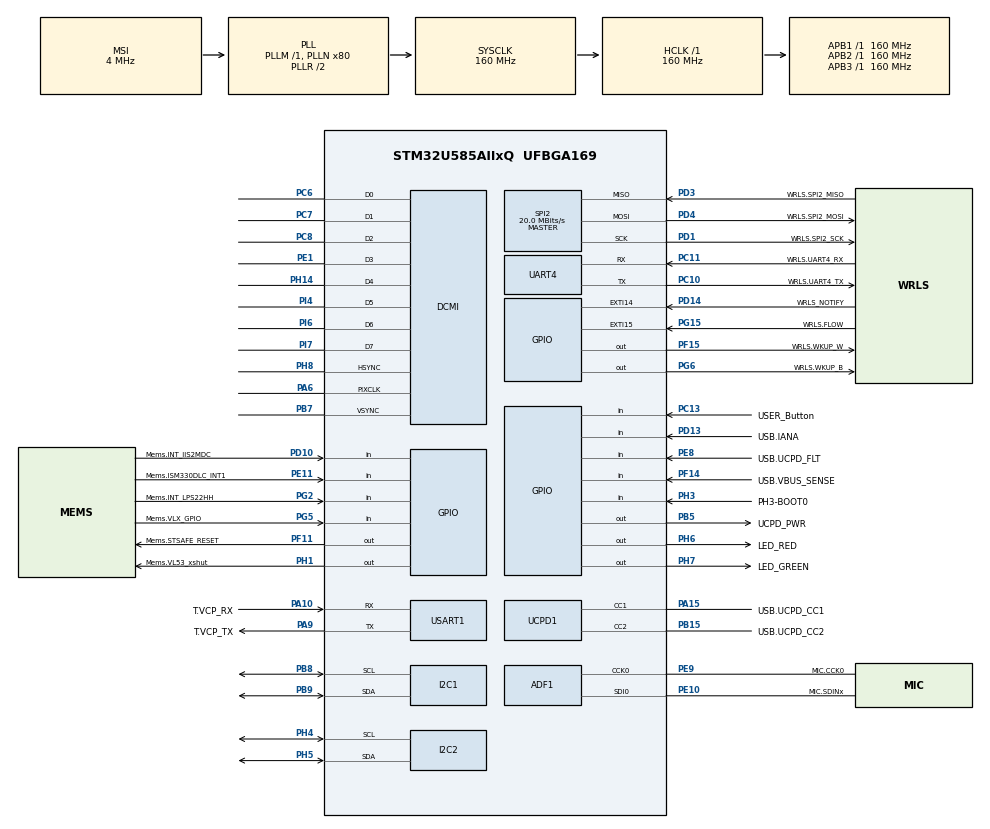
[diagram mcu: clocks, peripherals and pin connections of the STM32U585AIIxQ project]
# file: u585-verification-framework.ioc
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CORTEX_M33_NS.userName=CORTEX_M33
DCMI.HSPolarity=DCMI_HSPOLARITY_HIGH
DCMI.JPEGMode=DCMI_JPEG_ENABLE
DCMI.PCKPolarity=DCMI_PCKPOLARITY_RISING
DCMI.VSPolarity=DCMI_VSPOLARITY_HIGH
GPDMA1.DESTDATAWIDTH_GPDMACH0=DMA_DEST_DATAWIDTH_WORD
GPDMA1.DESTINC_GPDMACH0=DMA_DINC_INCREMENTED
GPDMA1.DESTINC_GPDMACH4=DMA_DINC_INCREMENTED
GPDMA1.IPHANDLE_GPDMACH0-SIMPLEREQUEST_GPDMACH0=__NULL
GPDMA1.IPHANDLE_GPDMACH4-SIMPLEREQUEST_GPDMACH4=__NULL
GPDMA1.IPHANDLE_GPDMACH5-SIMPLEREQUEST_GPDMACH5=__NULL
GPDMA1.PRIORITY_GPDMACH4=DMA_LOW_PRIORITY_HIGH_WEIGHT
GPDMA1.PRIORITY_GPDMACH5=DMA_LOW_PRIORITY_HIGH_WEIGHT
GPDMA1.RECAP_GPDMACH0=GPDMA1_REQUEST_DCMI
GPDMA1.REQUEST_GPDMACH0=GPDMA1_REQUEST_DCMI_PSSI
GPDMA1.REQUEST_GPDMACH4=GPDMA1_REQUEST_SPI2_RX
GPDMA1.REQUEST_GPDMACH5=GPDMA1_REQUEST_SPI2_TX
GPDMA1.SRCDATAWIDTH_GPDMACH0=DMA_SRC_DATAWIDTH_WORD
GPDMA1.SRCINC_GPDMACH5=DMA_SINC_INCREMENTED
GPDMA1.TRANSFERALLOCATEDPORTDEST_GPDMACH0=DMA_DEST_ALLOCATED_PORT1
GPDMA1.TRANSFERALLOCATEDPORTDEST_GPDMACH4=DMA_DEST_ALLOCATED_PORT1
GPDMA1.TRANSFERALLOCATEDPORTDEST_GPDMACH5=DMA_DEST_ALLOCATED_PORT1
I2C1.Timing=0x30909DEC
I2C2.Timing=0x30909DEC
Mcu.Family=STM32U5
Mcu.Name=STM32U585AIIxQ
Mcu.Package=UFBGA169
NETXDUO.NX_APP_MEM_POOL_SIZE=200*1024
NETXDUO.NX_DRIVER_DEFERRED_PROCESSING=true
NETXDUO.NX_ENABLE_EXTENDED_NOTIFY_SUPPORT=true
NETXDUO.NX_ENABLE_IP_PACKET_FILTER=true
NETXDUO.NX_PHYSICAL_HEADER=44
NVIC.DCMI_PSSI_IRQn=true\:0\:0\:false\:false\:true\:false\:true\:true\:true
NVIC.EXTI14_IRQn=true\:0\:0\:false\:false\:true\:false\:true\:true\:true
NVIC.EXTI15_IRQn=true\:0\:0\:false\:false\:true\:false\:true\:true\:true
NVIC.GPDMA1_Channel0_IRQn=true\:0\:0\:false\:false\:true\:true\:false\:true\:true
NVIC.GPDMA1_Channel4_IRQn=true\:0\:0\:false\:false\:true\:true\:false\:true\:true
NVIC.GPDMA1_Channel5_IRQn=true\:0\:0\:false\:false\:true\:true\:false\:true\:true
NVIC.PriorityGroup=NVIC_PRIORITYGROUP_4
NVIC.SPI2_IRQn=true\:0\:0\:false\:false\:true\:false\:false\:true\:true
NVIC.TIM6_IRQn=true\:15\:0\:false\:false\:true\:false\:false\:true\:true
NVIC.TimeBase=TIM6_IRQn
NVIC.TimeBaseIP=TIM6
PA10.GPIO_Label=T.VCP_RX
PA10.Mode=Asynchronous
PA10.Signal=USART1_RX
PA11.GPIO_Label=USB.C_P
PA11.Signal=USB_OTG_FS_DM
PA12.GPIO_Label=USB.C_P
PA12.Signal=USB_OTG_FS_DP
PA13\ (JTMS/SWDIO).GPIO_Label=T.SWDIO
PA13\ (JTMS/SWDIO).Mode=Trace_Asynchronous_SW
PA13\ (JTMS/SWDIO).Signal=DEBUG_JTMS-SWDIO
PA14\ (JTCK/SWCLK).GPIO_Label=T.SWCLK
PA14\ (JTCK/SWCLK).Mode=Trace_Asynchronous_SW
PA14\ (JTCK/SWCLK).Signal=DEBUG_JTCK-SWCLK
PA15\ (JTDI).GPIO_Label=USB.UCPD_CC1
PA15\ (JTDI).Mode=Dual_Role_AllSignals
PA15\ (JTDI).Signal=UCPD1_CC1
PA6.Mode=Slave_8_bits_External_Synchro
PA6.Signal=DCMI_PIXCLK
PA9.GPIO_Label=T.VCP_TX
PA9.Mode=Asynchronous
PA9.Signal=USART1_TX
PB1.GPIO_Label=MIC.SDIN0
PB1.Signal=MDF1_SDI0
PB10.GPIO_Label=OCTOSPI.R_CLK_P
PB10.Signal=OCTOSPIM_P1_CLK
PB11.GPIO_Label=OCTOSPI.R_NCS
PB11.Signal=OCTOSPIM_P1_NCS
PB12.GPIO_Label=WRLS.SPI2_NSS
PB12.Signal=SPI2_NSS
PB15.GPIO_Label=USB.UCPD_CC2
PB15.Mode=Dual_Role_AllSignals
PB15.Signal=UCPD1_CC2
PB3\ (JTDO/TRACESWO).GPIO_Label=T.SWO
PB3\ (JTDO/TRACESWO).Mode=Trace_Asynchronous_SW
PB3\ (JTDO/TRACESWO).Signal=DEBUG_JTDO-SWO
PB5.GPIO_Label=UCPD_PWR
PB5.Signal=GPIO_Output
PB7.Mode=Slave_8_bits_External_Synchro
PB7.Signal=DCMI_VSYNC
PB8.Mode=I2C
PB8.Signal=I2C1_SCL
PB9.Mode=I2C
PB9.Signal=I2C1_SDA
PC10.GPIO_Label=WRLS.UART4_TX
PC10.Mode=Asynchronous
PC10.Signal=UART4_TX
PC11.GPIO_Label=WRLS.UART4_RX
PC11.Mode=Asynchronous
PC11.Signal=UART4_RX
PC13.GPIO_Label=USER_Button
PC13.Signal=GPIO_Input
PC14-OSC32_IN\ (PC14).GPIO_Label=PC14-OSC32_IN
PC14-OSC32_IN\ (PC14).Mode=LSE-External-Oscillator
PC14-OSC32_IN\ (PC14).Signal=RCC_OSC32_IN
PC15-OSC32_OUT\ (PC15).GPIO_Label=PC15-OSC32_OUT
PC15-OSC32_OUT\ (PC15).Mode=LSE-External-Oscillator
PC15-OSC32_OUT\ (PC15).Signal=RCC_OSC32_OUT
PC3.GPIO_Label=OCTOSPI.R_IO6
PC3.Signal=OCTOSPIM_P1_IO6
PC6.Mode=Slave_8_bits_External_Synchro
PC6.Signal=DCMI_D0
PC7.Mode=Slave_8_bits_External_Synchro
PC7.Signal=DCMI_D1
PC8.Mode=Slave_8_bits_External_Synchro
PC8.Signal=DCMI_D2
PD1.GPIO_Label=WRLS.SPI2_SCK
PD1.Mode=Full_Duplex_Master
PD1.Signal=SPI2_SCK
PD10.GPIO_Label=Mems.INT_IIS2MDC
PD10.Signal=GPIO_Input
PD13.GPIO_Label=USB.IANA
PD13.Signal=GPIO_Input
PD14.GPIO_Label=WRLS_NOTIFY 
PD14.Signal=GPXTI14
PD3.GPIO_Label=WRLS.SPI2_MISO
PD3.Mode=Full_Duplex_Master
PD3.Signal=SPI2_MISO
PD4.GPIO_Label=WRLS.SPI2_MOSI
PD4.Mode=Full_Duplex_Master
PD4.Signal=SPI2_MOSI
PD7.GPIO_Label=OCTOSPI.R_IO7
PD7.Signal=OCTOSPIM_P1_IO7
PE1.Mode=Slave_8_bits_External_Synchro
PE1.Signal=DCMI_D3
PE10.GPIO_Label=MIC.SDINx
PE10.Mode=MOD_ADF_CCK
PE10.Signal=ADF1_SDI0
PE11.GPIO_Label=Mems.ISM330DLC_INT1
PE11.Signal=GPIO_Input
PE3.GPIO_Label=OCTOSPI.R_DQS
PE3.Signal=OCTOSPIM_P1_DQS
PE8.GPIO_Label=USB.UCPD_FLT
PE8.Signal=GPIO_Input
PE9.GPIO_Label=MIC.CCK0
PE9.Mode=MOD_MDF_CCK0
PE9.Signal=ADF1_CCK0
PF0.GPIO_Label=OCTOSPI.F_IO0
PF0.Signal=OCTOSPIM_P2_IO0
PF1.GPIO_Label=OCTOSPI.F_IO1
PF1.Signal=OCTOSPIM_P2_IO1
PF10.GPIO_Label=MIC.CCK1
PF10.Signal=MDF1_CCK1
PF11.GPIO_Label=Mems.STSAFE_RESET
PF11.Signal=GPIO_Output
PF12.GPIO_Label=OCTOSPI.F_DQS
PF12.Signal=OCTOSPIM_P2_DQS
PF14.GPIO_Label=USB.VBUS_SENSE
PF14.Signal=GPIO_Input
PF15.GPIO_Label=WRLS.WKUP_W
PF15.Signal=GPIO_Output
PF2.GPIO_Label=OCTOSPI.F_IO2
PF2.Signal=OCTOSPIM_P2_IO2
PF3.GPIO_Label=OCTOSPI.F_IO3
PF3.Signal=OCTOSPIM_P2_IO3
PF4.GPIO_Label=OCTOSPI.F_CLK_P
PF4.Signal=OCTOSPIM_P2_CLK
PF6.GPIO_Label=OCTOSPI.R_IO3
PF6.Signal=OCTOSPIM_P1_IO3
PF7.GPIO_Label=OCTOSPI.R_IO2
PF7.Signal=OCTOSPIM_P1_IO2
PF8.GPIO_Label=OCTOSPI.R_IO0
PF8.Signal=OCTOSPIM_P1_IO0
PF9.GPIO_Label=OCTOSPI.R_IO1
PF9.Signal=OCTOSPIM_P1_IO1
PG15.GPIO_Label=WRLS.FLOW
PG15.Signal=GPXTI15
PG2.GPIO_Label=Mems.INT_LPS22HH
PG2.Signal=GPIO_Input
PG5.GPIO_Label=Mems.VLX_GPIO
PG5.Signal=GPIO_Input
PG6.GPIO_Label=WRLS.WKUP_B
PG6.Signal=GPIO_Output
PH1-OSC_OUT\ (PH1).GPIO_Label=Mems.VL53_xshut
PH1-OSC_OUT\ (PH1).Signal=GPIO_Output
PH10.GPIO_Label=OCTOSPI.F_IO5
PH10.Signal=OCTOSPIM_P2_IO5
PH11.GPIO_Label=OCTOSPI.F_IO6
PH11.Signal=OCTOSPIM_P2_IO6
PH12.GPIO_Label=OCTOSPI.F_IO7
PH12.Signal=OCTOSPIM_P2_IO7
PH14.Mode=Slave_8_bits_External_Synchro
PH14.Signal=DCMI_D4
PH2.GPIO_Label=OCTOSPI.R_IO4
PH2.Signal=OCTOSPIM_P1_IO4
PH3-BOOT0.GPIO_Label=PH3-BOOT0
PH3-BOOT0.Signal=GPIO_Input
PH4.Mode=I2C
PH4.Signal=I2C2_SCL
PH5.Mode=I2C
PH5.Signal=I2C2_SDA
PH6.GPIO_Label=LED_RED
PH6.Signal=GPIO_Output
PH7.GPIO_Label=LED_GREEN
PH7.Signal=GPIO_Output
PH8.Mode=Slave_8_bits_External_Synchro
PH8.Signal=DCMI_HSYNC
PH9.GPIO_Label=OCTOSPI.F_IO4
PH9.Signal=OCTOSPIM_P2_IO4
PI0.GPIO_Label=OCTOSPI.R_IO5
PI0.Signal=OCTOSPIM_P1_IO5
PI4.Mode=Slave_8_bits_External_Synchro
PI4.Signal=DCMI_D5
PI5.GPIO_Label=OCTOSPI.F_NCS
PI5.Signal=OCTOSPIM_P2_NCS
PI6.Mode=Slave_8_bits_External_Synchro
PI6.Signal=DCMI_D6
PI7.Mode=Slave_8_bits_External_Synchro
PI7.Signal=DCMI_D7
PWR.PowerMode=PWR_SMPS_SUPPLY
ProjectManager.HeapSize=0x200
ProjectManager.StackSize=0x400
ProjectManager.TargetToolchain=CMake
RCC.ADCFreq_Value=16000000
RCC.AHBFreq_Value=160000000
RCC.APB1Freq_Value=160000000
RCC.APB1TimFreq_Value=160000000
RCC.APB2Freq_Value=160000000
RCC.APB2TimFreq_Value=160000000
RCC.APB3Freq_Value=160000000
RCC.CortexFreq_Value=160000000
RCC.DACCLockSelectionVirtual=RCC_DAC1CLKSOURCE_LSI
RCC.EPOD_VALUE=4000000
RCC.HCLKFreq_Value=160000000
RCC.HSE_VALUE=16000000
RCC.HSI48_VALUE=48000000
RCC.HSI_VALUE=16000000
RCC.LSIDIV_VALUE=32000
RCC.MSI_VALUE=4000000
RCC.PLLN=80
RCC.SYSCLKFreq_VALUE=160000000
RCC.SYSCLKSource=RCC_SYSCLKSOURCE_PLLCLK
RCC.USBFreq_Value=48000000
RCC.VCOOutputFreq_Value=320000000
SPI2.BaudRatePrescaler=SPI_BAUDRATEPRESCALER_8
SPI2.CalculateBaudRate=20.0 MBits/s
SPI2.DataSize=SPI_DATASIZE_8BIT
SPI2.Direction=SPI_DIRECTION_2LINES
SPI2.Mode=SPI_MODE_MASTER
SPI2.NSSPMode=SPI_NSS_PULSE_DISABLE
SPI2.VirtualType=VM_MASTER
THREADX.TX_APP_MEM_POOL_SIZE=4096
USART1.VirtualMode-Asynchronous=VM_ASYNC
VP_GPDMA1_VS_GPDMACH0.Mode=SIMPLEREQUEST_GPDMACH0
VP_GPDMA1_VS_GPDMACH4.Mode=SIMPLEREQUEST_GPDMACH4
VP_GPDMA1_VS_GPDMACH5.Mode=SIMPLEREQUEST_GPDMACH5
VP_ICACHE_VS_ICACHE.Mode=DirectMappedCache
VP_LPBAMQUEUE_VS_QUEUE.Mode=QUEUEMODE
VP_LPBAM_VS_SIG1.Mode=SmartRun
VP_LPBAM_VS_SIG4.Mode=LPDMA1
VP_MEMORYMAP_VS_MEMORYMAP.Mode=CurAppReg
VP_NETXDUO_VS_AddonsOoDHCP.Mode=Addons_DHCP_Client
VP_NETXDUO_VS_AddonsOoWebOoServer.Mode=Addons_Web_Server
VP_NETXDUO_VS_NXOoCore.Mode=NX_Core
VP_PWR_VS_DBSignals.Mode=DisableDeadBatterySignals
VP_PWR_VS_LPOM.Mode=PowerOptimisation
VP_PWR_VS_SECSignals.Mode=Security/Privilege
VP_SYS_VS_tim6.Mode=TIM6
VP_THREADX_VS_RTOSJjThreadXJjCoreJjDefault.Mode=Core_Default
VP_THREADX_VS_RTOSJjThreadXJjPerformance_InfoJjDefault.Mode=Performance_Default
board=B-U585I-IOT02A

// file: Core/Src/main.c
/* USER CODE BEGIN Header */
/**
  ******************************************************************************
  * @file           : main.c
  * @brief          : Main program body
  ******************************************************************************
  * @attention
  *
  * Copyright (c) 2026 STMicroelectronics.
  * All rights reserved.
  *
  * This software is licensed under terms that can be found in the LICENSE file
  * in the root directory of this software component.
  * If no LICENSE file comes with this software, it is provided AS-IS.
  *
  ******************************************************************************
  */
/* USER CODE END Header */
#include "app_threadx.h"
#include "main.h"

/* USER CODE BEGIN Includes */

#include "system.h"

/* USER CODE END Includes */

MDF_HandleTypeDef AdfHandle0;
MDF_FilterConfigTypeDef AdfFilterConfig0;

DCMI_HandleTypeDef hdcmi;
DMA_HandleTypeDef handle_GPDMA1_Channel0;

I2C_HandleTypeDef hi2c1;
I2C_HandleTypeDef hi2c2;

SPI_HandleTypeDef hspi2;
DMA_HandleTypeDef handle_GPDMA1_Channel5;
DMA_HandleTypeDef handle_GPDMA1_Channel4;

UART_HandleTypeDef huart4;
UART_HandleTypeDef huart1;

void SystemClock_Config(void);
static void SystemPower_Config(void);
static void MX_GPIO_Init(void);
static void MX_GPDMA1_Init(void);
static void MX_ADF1_Init(void);
static void MX_I2C1_Init(void);
static void MX_I2C2_Init(void);
static void MX_ICACHE_Init(void);
static void MX_SPI2_Init(void);
static void MX_UART4_Init(void);
static void MX_USART1_UART_Init(void);
static void MX_DCMI_Init(void);
static void MX_UCPD1_Init(void);

int main(void)
{

  /* MCU Configuration--------------------------------------------------------*/

  /* Reset of all peripherals, Initializes the Flash interface and the Systick. */
  HAL_Init();

  /* Configure the System Power */
  SystemPower_Config();

  /* Configure the system clock */
  SystemClock_Config();

  /* Initialize all configured peripherals */
  MX_GPIO_Init();
  MX_GPDMA1_Init();
  MX_ADF1_Init();
  MX_I2C1_Init();
  MX_I2C2_Init();
  MX_ICACHE_Init();
  MX_SPI2_Init();
  MX_UART4_Init();
  MX_USART1_UART_Init();
  MX_DCMI_Init();
  MX_UCPD1_Init();
  /* USER CODE BEGIN 2 */

  System_Init();

  /* USER CODE END 2 */

  MX_ThreadX_Init();

  /* We should never get here as control is now taken by the scheduler */

  /* Infinite loop */
  while (1)
  {

    /* USER CODE BEGIN 3 */

    /* Unreachable: tx_kernel_enter() inside MX_ThreadX_Init() above never
     * returns. Sensor polling now runs in the "System Thread" started by
     * App_ThreadX_Init() (Core/Src/app_threadx.c). */

  }
  /* USER CODE END 3 */
}

void SystemClock_Config(void)
{
  RCC_OscInitTypeDef RCC_OscInitStruct = {0};
  RCC_ClkInitTypeDef RCC_ClkInitStruct = {0};

  /** Configure the main internal regulator output voltage
  */
  if (HAL_PWREx_ControlVoltageScaling(PWR_REGULATOR_VOLTAGE_SCALE1) != HAL_OK)
  {
    Error_Handler();
  }

  /** Initializes the CPU, AHB and APB buses clocks
  */
  RCC_OscInitStruct.OscillatorType = RCC_OSCILLATORTYPE_HSI|RCC_OSCILLATORTYPE_MSI;
  RCC_OscInitStruct.HSIState = RCC_HSI_ON;
  RCC_OscInitStruct.HSICalibrationValue = RCC_HSICALIBRATION_DEFAULT;
  RCC_OscInitStruct.MSIState = RCC_MSI_ON;
  RCC_OscInitStruct.MSICalibrationValue = RCC_MSICALIBRATION_DEFAULT;
  RCC_OscInitStruct.MSIClockRange = RCC_MSIRANGE_4;
  RCC_OscInitStruct.PLL.PLLState = RCC_PLL_ON;
  RCC_OscInitStruct.PLL.PLLSource = RCC_PLLSOURCE_MSI;
  RCC_OscInitStruct.PLL.PLLMBOOST = RCC_PLLMBOOST_DIV1;
  RCC_OscInitStruct.PLL.PLLM = 1;
  RCC_OscInitStruct.PLL.PLLN = 80;
  RCC_OscInitStruct.PLL.PLLP = 2;
  RCC_OscInitStruct.PLL.PLLQ = 2;
  RCC_OscInitStruct.PLL.PLLR = 2;
  RCC_OscInitStruct.PLL.PLLRGE = RCC_PLLVCIRANGE_0;
  RCC_OscInitStruct.PLL.PLLFRACN = 0;
  if (HAL_RCC_OscConfig(&RCC_OscInitStruct) != HAL_OK)
  {
    Error_Handler();
  }

  /** Initializes the CPU, AHB and APB buses clocks
  */
  RCC_ClkInitStruct.ClockType = RCC_CLOCKTYPE_HCLK|RCC_CLOCKTYPE_SYSCLK
                              |RCC_CLOCKTYPE_PCLK1|RCC_CLOCKTYPE_PCLK2
                              |RCC_CLOCKTYPE_PCLK3;
  RCC_ClkInitStruct.SYSCLKSource = RCC_SYSCLKSOURCE_PLLCLK;
  RCC_ClkInitStruct.AHBCLKDivider = RCC_SYSCLK_DIV1;
  RCC_ClkInitStruct.APB1CLKDivider = RCC_HCLK_DIV1;
  RCC_ClkInitStruct.APB2CLKDivider = RCC_HCLK_DIV1;
  RCC_ClkInitStruct.APB3CLKDivider = RCC_HCLK_DIV1;

  if (HAL_RCC_ClockConfig(&RCC_ClkInitStruct, FLASH_LATENCY_4) != HAL_OK)
  {
    Error_Handler();
  }
}

/**
  * @brief Power Configuration
  * @retval None
  */
static void SystemPower_Config(void)
{
  HAL_PWREx_EnableVddIO2();

  /*
   * Switch to SMPS regulator instead of LDO
   */
  if (HAL_PWREx_ConfigSupply(PWR_SMPS_SUPPLY) != HAL_OK)
  {
    Error_Handler();
  }
}

static void MX_ADF1_Init(void)
{

  /**
    AdfHandle0 structure initialization and HAL_MDF_Init function call
  */
  AdfHandle0.Instance = ADF1_Filter0;
  AdfHandle0.Init.CommonParam.ProcClockDivider = 1;
  AdfHandle0.Init.CommonParam.OutputClock.Activation = DISABLE;
  AdfHandle0.Init.SerialInterface.Activation = ENABLE;
  AdfHandle0.Init.SerialInterface.Mode = MDF_SITF_LF_MASTER_SPI_MODE;
  AdfHandle0.Init.SerialInterface.ClockSource = MDF_SITF_CCK0_SOURCE;
  AdfHandle0.Init.SerialInterface.Threshold = 4;
  AdfHandle0.Init.FilterBistream = MDF_BITSTREAM0_FALLING;
  if (HAL_MDF_Init(&AdfHandle0) != HAL_OK)
  {
    Error_Handler();
  }

  /**
    AdfFilterConfig0 structure initialization

    WARNING : only structure is filled, no specific init function call for filter
  */
  AdfFilterConfig0.DataSource = MDF_DATA_SOURCE_BSMX;
  AdfFilterConfig0.Delay = 0;
  AdfFilterConfig0.CicMode = MDF_ONE_FILTER_SINC4;
  AdfFilterConfig0.DecimationRatio = 2;
  AdfFilterConfig0.Gain = 0;
  AdfFilterConfig0.ReshapeFilter.Activation = DISABLE;
  AdfFilterConfig0.HighPassFilter.Activation = DISABLE;
  AdfFilterConfig0.SoundActivity.Activation = DISABLE;
  AdfFilterConfig0.AcquisitionMode = MDF_MODE_ASYNC_CONT;
  AdfFilterConfig0.FifoThreshold = MDF_FIFO_THRESHOLD_NOT_EMPTY;
  AdfFilterConfig0.DiscardSamples = 0;

}

static void MX_DCMI_Init(void)
{

  hdcmi.Instance = DCMI;
  hdcmi.Init.SynchroMode = DCMI_SYNCHRO_HARDWARE;
  hdcmi.Init.PCKPolarity = DCMI_PCKPOLARITY_RISING;
  hdcmi.Init.VSPolarity = DCMI_VSPOLARITY_HIGH;
  hdcmi.Init.HSPolarity = DCMI_HSPOLARITY_HIGH;
  hdcmi.Init.CaptureRate = DCMI_CR_ALL_FRAME;
  hdcmi.Init.ExtendedDataMode = DCMI_EXTEND_DATA_8B;
  hdcmi.Init.JPEGMode = DCMI_JPEG_ENABLE;
  hdcmi.Init.ByteSelectMode = DCMI_BSM_ALL;
  hdcmi.Init.ByteSelectStart = DCMI_OEBS_ODD;
  hdcmi.Init.LineSelectMode = DCMI_LSM_ALL;
  hdcmi.Init.LineSelectStart = DCMI_OELS_ODD;
  if (HAL_DCMI_Init(&hdcmi) != HAL_OK)
  {
    Error_Handler();
  }

}

static void MX_GPDMA1_Init(void)
{

  /* Peripheral clock enable */
  __HAL_RCC_GPDMA1_CLK_ENABLE();

  /* GPDMA1 interrupt Init */
    HAL_NVIC_SetPriority(GPDMA1_Channel0_IRQn, 0, 0);
    HAL_NVIC_EnableIRQ(GPDMA1_Channel0_IRQn);
    HAL_NVIC_SetPriority(GPDMA1_Channel4_IRQn, 0, 0);
    HAL_NVIC_EnableIRQ(GPDMA1_Channel4_IRQn);
    HAL_NVIC_SetPriority(GPDMA1_Channel5_IRQn, 0, 0);
    HAL_NVIC_EnableIRQ(GPDMA1_Channel5_IRQn);

}

static void MX_I2C1_Init(void)
{

  hi2c1.Instance = I2C1;
  hi2c1.Init.Timing = 0x30909DEC;
  hi2c1.Init.OwnAddress1 = 0;
  hi2c1.Init.AddressingMode = I2C_ADDRESSINGMODE_7BIT;
  hi2c1.Init.DualAddressMode = I2C_DUALADDRESS_DISABLE;
  hi2c1.Init.OwnAddress2 = 0;
  hi2c1.Init.OwnAddress2Masks = I2C_OA2_NOMASK;
  hi2c1.Init.GeneralCallMode = I2C_GENERALCALL_DISABLE;
  hi2c1.Init.NoStretchMode = I2C_NOSTRETCH_DISABLE;
  if (HAL_I2C_Init(&hi2c1) != HAL_OK)
  {
    Error_Handler();
  }

  /** Configure Analogue filter
  */
  if (HAL_I2CEx_ConfigAnalogFilter(&hi2c1, I2C_ANALOGFILTER_ENABLE) != HAL_OK)
  {
    Error_Handler();
  }

  /** Configure Digital filter
  */
  if (HAL_I2CEx_ConfigDigitalFilter(&hi2c1, 0) != HAL_OK)
  {
    Error_Handler();
  }

}

static void MX_I2C2_Init(void)
{

  hi2c2.Instance = I2C2;
  hi2c2.Init.Timing = 0x30909DEC;
  hi2c2.Init.OwnAddress1 = 0;
  hi2c2.Init.AddressingMode = I2C_ADDRESSINGMODE_7BIT;
  hi2c2.Init.DualAddressMode = I2C_DUALADDRESS_DISABLE;
  hi2c2.Init.OwnAddress2 = 0;
  hi2c2.Init.OwnAddress2Masks = I2C_OA2_NOMASK;
  hi2c2.Init.GeneralCallMode = I2C_GENERALCALL_DISABLE;
  hi2c2.Init.NoStretchMode = I2C_NOSTRETCH_DISABLE;
  if (HAL_I2C_Init(&hi2c2) != HAL_OK)
  {
    Error_Handler();
  }

  /** Configure Analogue filter
  */
  if (HAL_I2CEx_ConfigAnalogFilter(&hi2c2, I2C_ANALOGFILTER_ENABLE) != HAL_OK)
  {
    Error_Handler();
  }

  /** Configure Digital filter
  */
  if (HAL_I2CEx_ConfigDigitalFilter(&hi2c2, 0) != HAL_OK)
  {
    Error_Handler();
  }

}

static void MX_ICACHE_Init(void)
{

  /** Enable instruction cache in 1-way (direct mapped cache)
  */
  if (HAL_ICACHE_ConfigAssociativityMode(ICACHE_1WAY) != HAL_OK)
  {
    Error_Handler();
  }
  if (HAL_ICACHE_Enable() != HAL_OK)
  {
    Error_Handler();
  }

}

static void MX_SPI2_Init(void)
{

  SPI_AutonomousModeConfTypeDef HAL_SPI_AutonomousMode_Cfg_Struct = {0};

  /* SPI2 parameter configuration*/
  hspi2.Instance = SPI2;
  hspi2.Init.Mode = SPI_MODE_MASTER;
  hspi2.Init.Direction = SPI_DIRECTION_2LINES;
  hspi2.Init.DataSize = SPI_DATASIZE_8BIT;
  hspi2.Init.CLKPolarity = SPI_POLARITY_LOW;
  hspi2.Init.CLKPhase = SPI_PHASE_1EDGE;
  hspi2.Init.NSS = SPI_NSS_SOFT;
  hspi2.Init.BaudRatePrescaler = SPI_BAUDRATEPRESCALER_8;
  hspi2.Init.FirstBit = SPI_FIRSTBIT_MSB;
  hspi2.Init.TIMode = SPI_TIMODE_DISABLE;
  hspi2.Init.CRCCalculation = SPI_CRCCALCULATION_DISABLE;
  hspi2.Init.CRCPolynomial = 0x7;
  hspi2.Init.NSSPMode = SPI_NSS_PULSE_DISABLE;
  hspi2.Init.NSSPolarity = SPI_NSS_POLARITY_LOW;
  hspi2.Init.FifoThreshold = SPI_FIFO_THRESHOLD_01DATA;
  hspi2.Init.MasterSSIdleness = SPI_MASTER_SS_IDLENESS_00CYCLE;
  hspi2.Init.MasterInterDataIdleness = SPI_MASTER_INTERDATA_IDLENESS_00CYCLE;
  hspi2.Init.MasterReceiverAutoSusp = SPI_MASTER_RX_AUTOSUSP_DISABLE;
  hspi2.Init.MasterKeepIOState = SPI_MASTER_KEEP_IO_STATE_DISABLE;
  hspi2.Init.IOSwap = SPI_IO_SWAP_DISABLE;
  hspi2.Init.ReadyMasterManagement = SPI_RDY_MASTER_MANAGEMENT_INTERNALLY;
  hspi2.Init.ReadyPolarity = SPI_RDY_POLARITY_HIGH;
  if (HAL_SPI_Init(&hspi2) != HAL_OK)
  {
    Error_Handler();
  }
  HAL_SPI_AutonomousMode_Cfg_Struct.TriggerState = SPI_AUTO_MODE_DISABLE;
  HAL_SPI_AutonomousMode_Cfg_Struct.TriggerSelection = SPI_GRP1_GPDMA_CH0_TCF_TRG;
  HAL_SPI_AutonomousMode_Cfg_Struct.TriggerPolarity = SPI_TRIG_POLARITY_RISING;
  if (HAL_SPIEx_SetConfigAutonomousMode(&hspi2, &HAL_SPI_AutonomousMode_Cfg_Struct) != HAL_OK)
  {
    Error_Handler();
  }

}

static void MX_UART4_Init(void)
{

  huart4.Instance = UART4;
  huart4.Init.BaudRate = 115200;
  huart4.Init.WordLength = UART_WORDLENGTH_8B;
  huart4.Init.StopBits = UART_STOPBITS_1;
  huart4.Init.Parity = UART_PARITY_NONE;
  huart4.Init.Mode = UART_MODE_TX_RX;
  huart4.Init.HwFlowCtl = UART_HWCONTROL_NONE;
  huart4.Init.OverSampling = UART_OVERSAMPLING_16;
  huart4.Init.OneBitSampling = UART_ONE_BIT_SAMPLE_DISABLE;
  huart4.Init.ClockPrescaler = UART_PRESCALER_DIV1;
  huart4.AdvancedInit.AdvFeatureInit = UART_ADVFEATURE_NO_INIT;
  if (HAL_UART_Init(&huart4) != HAL_OK)
  {
    Error_Handler();
  }
  if (HAL_UARTEx_SetTxFifoThreshold(&huart4, UART_TXFIFO_THRESHOLD_1_8) != HAL_OK)
  {
    Error_Handler();
  }
  if (HAL_UARTEx_SetRxFifoThreshold(&huart4, UART_RXFIFO_THRESHOLD_1_8) != HAL_OK)
  {
    Error_Handler();
  }
  if (HAL_UARTEx_DisableFifoMode(&huart4) != HAL_OK)
  {
    Error_Handler();
  }

}

static void MX_USART1_UART_Init(void)
{

  huart1.Instance = USART1;
  huart1.Init.BaudRate = 115200;
  huart1.Init.WordLength = UART_WORDLENGTH_8B;
  huart1.Init.StopBits = UART_STOPBITS_1;
  huart1.Init.Parity = UART_PARITY_NONE;
  huart1.Init.Mode = UART_MODE_TX_RX;
  huart1.Init.HwFlowCtl = UART_HWCONTROL_NONE;
  huart1.Init.OverSampling = UART_OVERSAMPLING_16;
  huart1.Init.OneBitSampling = UART_ONE_BIT_SAMPLE_DISABLE;
  huart1.Init.ClockPrescaler = UART_PRESCALER_DIV1;
  huart1.AdvancedInit.AdvFeatureInit = UART_ADVFEATURE_NO_INIT;
  if (HAL_UART_Init(&huart1) != HAL_OK)
  {
    Error_Handler();
  }
  if (HAL_UARTEx_SetTxFifoThreshold(&huart1, UART_TXFIFO_THRESHOLD_1_8) != HAL_OK)
  {
    Error_Handler();
  }
  if (HAL_UARTEx_SetRxFifoThreshold(&huart1, UART_RXFIFO_THRESHOLD_1_8) != HAL_OK)
  {
    Error_Handler();
  }
  if (HAL_UARTEx_DisableFifoMode(&huart1) != HAL_OK)
  {
    Error_Handler();
  }

}

static void MX_UCPD1_Init(void)
{

  LL_GPIO_InitTypeDef GPIO_InitStruct = {0};

  /* Peripheral clock enable */
  LL_APB1_GRP2_EnableClock(LL_APB1_GRP2_PERIPH_UCPD1);

  LL_AHB2_GRP1_EnableClock(LL_AHB2_GRP1_PERIPH_GPIOA);
  LL_AHB2_GRP1_EnableClock(LL_AHB2_GRP1_PERIPH_GPIOB);
  /**UCPD1 GPIO Configuration
  PA15 (JTDI)   ------> UCPD1_CC1
  PB15   ------> UCPD1_CC2
  */
  GPIO_InitStruct.Pin = LL_GPIO_PIN_15;
  GPIO_InitStruct.Mode = LL_GPIO_MODE_ANALOG;
  GPIO_InitStruct.Pull = LL_GPIO_PULL_NO;
  LL_GPIO_Init(GPIOA, &GPIO_InitStruct);

  GPIO_InitStruct.Pin = LL_GPIO_PIN_15;
  GPIO_InitStruct.Mode = LL_GPIO_MODE_ANALOG;
  GPIO_InitStruct.Pull = LL_GPIO_PULL_NO;
  LL_GPIO_Init(GPIOB, &GPIO_InitStruct);

}

static void MX_GPIO_Init(void)
{
  GPIO_InitTypeDef GPIO_InitStruct = {0};

  /* GPIO Ports Clock Enable */
  __HAL_RCC_GPIOI_CLK_ENABLE();
  __HAL_RCC_GPIOG_CLK_ENABLE();
  __HAL_RCC_GPIOC_CLK_ENABLE();
  __HAL_RCC_GPIOA_CLK_ENABLE();
  __HAL_RCC_GPIOH_CLK_ENABLE();
  __HAL_RCC_GPIOE_CLK_ENABLE();
  __HAL_RCC_GPIOB_CLK_ENABLE();
  __HAL_RCC_GPIOD_CLK_ENABLE();
  __HAL_RCC_GPIOF_CLK_ENABLE();

  /*Configure GPIO pin Output Level */
  HAL_GPIO_WritePin(UCPD_PWR_GPIO_Port, UCPD_PWR_Pin, GPIO_PIN_RESET);

  /*Configure GPIO pin Output Level */
  HAL_GPIO_WritePin(GPIOH, LED_RED_Pin|LED_GREEN_Pin|Mems_VL53_xshut_Pin, GPIO_PIN_RESET);

  /*Configure GPIO pin Output Level */
  HAL_GPIO_WritePin(WRLS_WKUP_B_GPIO_Port, WRLS_WKUP_B_Pin, GPIO_PIN_RESET);

  /*Configure GPIO pin Output Level */
  HAL_GPIO_WritePin(GPIOF, Mems_STSAFE_RESET_Pin|WRLS_WKUP_W_Pin, GPIO_PIN_RESET);

  /*Configure GPIO pin : WRLS_FLOW_Pin */
  GPIO_InitStruct.Pin = WRLS_FLOW_Pin;
  GPIO_InitStruct.Mode = GPIO_MODE_IT_RISING;
  GPIO_InitStruct.Pull = GPIO_NOPULL;
  HAL_GPIO_Init(WRLS_FLOW_GPIO_Port, &GPIO_InitStruct);

  /*Configure GPIO pin : OCTOSPI_F_NCS_Pin */
  GPIO_InitStruct.Pin = OCTOSPI_F_NCS_Pin;
  GPIO_InitStruct.Mode = GPIO_MODE_AF_PP;
  GPIO_InitStruct.Pull = GPIO_NOPULL;
  GPIO_InitStruct.Speed = GPIO_SPEED_FREQ_VERY_HIGH;
  GPIO_InitStruct.Alternate = GPIO_AF5_OCTOSPI2;
  HAL_GPIO_Init(OCTOSPI_F_NCS_GPIO_Port, &GPIO_InitStruct);

  /*Configure GPIO pin : OCTOSPI_R_IO5_Pin */
  GPIO_InitStruct.Pin = OCTOSPI_R_IO5_Pin;
  GPIO_InitStruct.Mode = GPIO_MODE_AF_PP;
  GPIO_InitStruct.Pull = GPIO_NOPULL;
  GPIO_InitStruct.Speed = GPIO_SPEED_FREQ_VERY_HIGH;
  GPIO_InitStruct.Alternate = GPIO_AF3_OCTOSPI1;
  HAL_GPIO_Init(OCTOSPI_R_IO5_GPIO_Port, &GPIO_InitStruct);

  /*Configure GPIO pins : OCTOSPI_F_IO7_Pin OCTOSPI_F_IO5_Pin OCTOSPI_F_IO6_Pin OCTOSPI_F_IO4_Pin */
  GPIO_InitStruct.Pin = OCTOSPI_F_IO7_Pin|OCTOSPI_F_IO5_Pin|OCTOSPI_F_IO6_Pin|OCTOSPI_F_IO4_Pin;
  GPIO_InitStruct.Mode = GPIO_MODE_AF_PP;
  GPIO_InitStruct.Pull = GPIO_NOPULL;
  GPIO_InitStruct.Speed = GPIO_SPEED_FREQ_VERY_HIGH;
  GPIO_InitStruct.Alternate = GPIO_AF5_OCTOSPI2;
  HAL_GPIO_Init(GPIOH, &GPIO_InitStruct);

  /*Configure GPIO pin : PH3_BOOT0_Pin */
  GPIO_InitStruct.Pin = PH3_BOOT0_Pin;
  GPIO_InitStruct.Mode = GPIO_MODE_INPUT;
  GPIO_InitStruct.Pull = GPIO_NOPULL;
  HAL_GPIO_Init(PH3_BOOT0_GPIO_Port, &GPIO_InitStruct);

  /*Configure GPIO pin : UCPD_PWR_Pin */
  GPIO_InitStruct.Pin = UCPD_PWR_Pin;
  GPIO_InitStruct.Mode = GPIO_MODE_OUTPUT_PP;
  GPIO_InitStruct.Pull = GPIO_NOPULL;
  GPIO_InitStruct.Speed = GPIO_SPEED_FREQ_LOW;
  HAL_GPIO_Init(UCPD_PWR_GPIO_Port, &GPIO_InitStruct);

  /*Configure GPIO pin : OCTOSPI_R_DQS_Pin */
  GPIO_InitStruct.Pin = OCTOSPI_R_DQS_Pin;
  GPIO_InitStruct.Mode = GPIO_MODE_AF_PP;
  GPIO_InitStruct.Pull = GPIO_NOPULL;
  GPIO_InitStruct.Speed = GPIO_SPEED_FREQ_VERY_HIGH;
  GPIO_InitStruct.Alternate = GPIO_AF3_OCTOSPI1;
  HAL_GPIO_Init(OCTOSPI_R_DQS_GPIO_Port, &GPIO_InitStruct);

  /*Configure GPIO pin : OCTOSPI_R_IO7_Pin */
  GPIO_InitStruct.Pin = OCTOSPI_R_IO7_Pin;
  GPIO_InitStruct.Mode = GPIO_MODE_AF_PP;
  GPIO_InitStruct.Pull = GPIO_NOPULL;
  GPIO_InitStruct.Speed = GPIO_SPEED_FREQ_VERY_HIGH;
  GPIO_InitStruct.Alternate = GPIO_AF10_OCTOSPI1;
  HAL_GPIO_Init(OCTOSPI_R_IO7_GPIO_Port, &GPIO_InitStruct);

  /*Configure GPIO pins : OCTOSPI_F_IO0_Pin OCTOSPI_F_IO1_Pin OCTOSPI_F_IO2_Pin OCTOSPI_F_IO3_Pin
                           OCTOSPI_F_CLK_P_Pin OCTOSPI_F_DQS_Pin */
  GPIO_InitStruct.Pin = OCTOSPI_F_IO0_Pin|OCTOSPI_F_IO1_Pin|OCTOSPI_F_IO2_Pin|OCTOSPI_F_IO3_Pin
                          |OCTOSPI_F_CLK_P_Pin|OCTOSPI_F_DQS_Pin;
  GPIO_InitStruct.Mode = GPIO_MODE_AF_PP;
  GPIO_InitStruct.Pull = GPIO_NOPULL;
  GPIO_InitStruct.Speed = GPIO_SPEED_FREQ_VERY_HIGH;
  GPIO_InitStruct.Alternate = GPIO_AF5_OCTOSPI2;
  HAL_GPIO_Init(GPIOF, &GPIO_InitStruct);

  /*Configure GPIO pin : USER_Button_Pin */
  GPIO_InitStruct.Pin = USER_Button_Pin;
  GPIO_InitStruct.Mode = GPIO_MODE_INPUT;
  GPIO_InitStruct.Pull = GPIO_NOPULL;
  HAL_GPIO_Init(USER_Button_GPIO_Port, &GPIO_InitStruct);

  /*Configure GPIO pins : LED_RED_Pin LED_GREEN_Pin Mems_VL53_xshut_Pin */
  GPIO_InitStruct.Pin = LED_RED_Pin|LED_GREEN_Pin|Mems_VL53_xshut_Pin;
  GPIO_InitStruct.Mode = GPIO_MODE_OUTPUT_PP;
  GPIO_InitStruct.Pull = GPIO_NOPULL;
  GPIO_InitStruct.Speed = GPIO_SPEED_FREQ_LOW;
  HAL_GPIO_Init(GPIOH, &GPIO_InitStruct);

  /*Configure GPIO pins : OCTOSPI_R_IO0_Pin OCTOSPI_R_IO2_Pin OCTOSPI_R_IO1_Pin OCTOSPI_R_IO3_Pin */
  GPIO_InitStruct.Pin = OCTOSPI_R_IO0_Pin|OCTOSPI_R_IO2_Pin|OCTOSPI_R_IO1_Pin|OCTOSPI_R_IO3_Pin;
  GPIO_InitStruct.Mode = GPIO_MODE_AF_PP;
  GPIO_InitStruct.Pull = GPIO_NOPULL;
  GPIO_InitStruct.Speed = GPIO_SPEED_FREQ_VERY_HIGH;
  GPIO_InitStruct.Alternate = GPIO_AF10_OCTOSPI1;
  HAL_GPIO_Init(GPIOF, &GPIO_InitStruct);

  /*Configure GPIO pin : OCTOSPI_R_IO4_Pin */
  GPIO_InitStruct.Pin = OCTOSPI_R_IO4_Pin;
  GPIO_InitStruct.Mode = GPIO_MODE_AF_PP;
  GPIO_InitStruct.Pull = GPIO_NOPULL;
  GPIO_InitStruct.Speed = GPIO_SPEED_FREQ_VERY_HIGH;
  GPIO_InitStruct.Alternate = GPIO_AF3_OCTOSPI1;
  HAL_GPIO_Init(OCTOSPI_R_IO4_GPIO_Port, &GPIO_InitStruct);

  /*Configure GPIO pins : USB_C_P_Pin USB_C_PA11_Pin */
  GPIO_InitStruct.Pin = USB_C_P_Pin|USB_C_PA11_Pin;
  GPIO_InitStruct.Mode = GPIO_MODE_AF_PP;
  GPIO_InitStruct.Pull = GPIO_NOPULL;
  GPIO_InitStruct.Speed = GPIO_SPEED_FREQ_LOW;
  GPIO_InitStruct.Alternate = GPIO_AF10_USB;
  HAL_GPIO_Init(GPIOA, &GPIO_InitStruct);

  /*Configure GPIO pin : MIC_CCK1_Pin */
  GPIO_InitStruct.Pin = MIC_CCK1_Pin;
  GPIO_InitStruct.Mode = GPIO_MODE_AF_PP;
  GPIO_InitStruct.Pull = GPIO_NOPULL;
  GPIO_InitStruct.Speed = GPIO_SPEED_FREQ_LOW;
  GPIO_InitStruct.Alternate = GPIO_AF6_MDF1;
  HAL_GPIO_Init(MIC_CCK1_GPIO_Port, &GPIO_InitStruct);

  /*Configure GPIO pin : WRLS_WKUP_B_Pin */
  GPIO_InitStruct.Pin = WRLS_WKUP_B_Pin;
  GPIO_InitStruct.Mode = GPIO_MODE_OUTPUT_PP;
  GPIO_InitStruct.Pull = GPIO_NOPULL;
  GPIO_InitStruct.Speed = GPIO_SPEED_FREQ_LOW;
  HAL_GPIO_Init(WRLS_WKUP_B_GPIO_Port, &GPIO_InitStruct);

  /*Configure GPIO pins : Mems_VLX_GPIO_Pin Mems_INT_LPS22HH_Pin */
  GPIO_InitStruct.Pin = Mems_VLX_GPIO_Pin|Mems_INT_LPS22HH_Pin;
  GPIO_InitStruct.Mode = GPIO_MODE_INPUT;
  GPIO_InitStruct.Pull = GPIO_NOPULL;
  HAL_GPIO_Init(GPIOG, &GPIO_InitStruct);

  /*Configure GPIO pin : WRLS_NOTIFY_Pin */
  GPIO_InitStruct.Pin = WRLS_NOTIFY_Pin;
  GPIO_InitStruct.Mode = GPIO_MODE_IT_RISING;
  GPIO_InitStruct.Pull = GPIO_NOPULL;
  HAL_GPIO_Init(WRLS_NOTIFY_GPIO_Port, &GPIO_InitStruct);

  /*Configure GPIO pin : OCTOSPI_R_IO6_Pin */
  GPIO_InitStruct.Pin = OCTOSPI_R_IO6_Pin;
  GPIO_InitStruct.Mode = GPIO_MODE_AF_PP;
  GPIO_InitStruct.Pull = GPIO_NOPULL;
  GPIO_InitStruct.Speed = GPIO_SPEED_FREQ_VERY_HIGH;
  GPIO_InitStruct.Alternate = GPIO_AF10_OCTOSPI1;
  HAL_GPIO_Init(OCTOSPI_R_IO6_GPIO_Port, &GPIO_InitStruct);

  /*Configure GPIO pins : USB_UCPD_FLT_Pin Mems_ISM330DLC_INT1_Pin */
  GPIO_InitStruct.Pin = USB_UCPD_FLT_Pin|Mems_ISM330DLC_INT1_Pin;
  GPIO_InitStruct.Mode = GPIO_MODE_INPUT;
  GPIO_InitStruct.Pull = GPIO_NOPULL;
  HAL_GPIO_Init(GPIOE, &GPIO_InitStruct);

  /*Configure GPIO pins : OCTOSPI_R_CLK_P_Pin OCTOSPI_R_NCS_Pin */
  GPIO_InitStruct.Pin = OCTOSPI_R_CLK_P_Pin|OCTOSPI_R_NCS_Pin;
  GPIO_InitStruct.Mode = GPIO_MODE_AF_PP;
  GPIO_InitStruct.Pull = GPIO_NOPULL;
  GPIO_InitStruct.Speed = GPIO_SPEED_FREQ_VERY_HIGH;
  GPIO_InitStruct.Alternate = GPIO_AF10_OCTOSPI1;
  HAL_GPIO_Init(GPIOB, &GPIO_InitStruct);

  /*Configure GPIO pins : Mems_INT_IIS2MDC_Pin USB_IANA_Pin */
  GPIO_InitStruct.Pin = Mems_INT_IIS2MDC_Pin|USB_IANA_Pin;
  GPIO_InitStruct.Mode = GPIO_MODE_INPUT;
  GPIO_InitStruct.Pull = GPIO_NOPULL;
  HAL_GPIO_Init(GPIOD, &GPIO_InitStruct);

  /*Configure GPIO pin : USB_VBUS_SENSE_Pin */
  GPIO_InitStruct.Pin = USB_VBUS_SENSE_Pin;
  GPIO_InitStruct.Mode = GPIO_MODE_INPUT;
  GPIO_InitStruct.Pull = GPIO_NOPULL;
  HAL_GPIO_Init(USB_VBUS_SENSE_GPIO_Port, &GPIO_InitStruct);

  /*Configure GPIO pins : Mems_STSAFE_RESET_Pin WRLS_WKUP_W_Pin */
  GPIO_InitStruct.Pin = Mems_STSAFE_RESET_Pin|WRLS_WKUP_W_Pin;
  GPIO_InitStruct.Mode = GPIO_MODE_OUTPUT_PP;
  GPIO_InitStruct.Pull = GPIO_NOPULL;
  GPIO_InitStruct.Speed = GPIO_SPEED_FREQ_LOW;
  HAL_GPIO_Init(GPIOF, &GPIO_InitStruct);

  /*Configure GPIO pin : MIC_SDIN0_Pin */
  GPIO_InitStruct.Pin = MIC_SDIN0_Pin;
  GPIO_InitStruct.Mode = GPIO_MODE_AF_PP;
  GPIO_InitStruct.Pull = GPIO_NOPULL;
  GPIO_InitStruct.Speed = GPIO_SPEED_FREQ_LOW;
  GPIO_InitStruct.Alternate = GPIO_AF6_MDF1;
  HAL_GPIO_Init(MIC_SDIN0_GPIO_Port, &GPIO_InitStruct);

  /* EXTI interrupt init*/
  HAL_NVIC_SetPriority(EXTI14_IRQn, 0, 0);
  HAL_NVIC_EnableIRQ(EXTI14_IRQn);

  HAL_NVIC_SetPriority(EXTI15_IRQn, 0, 0);
  HAL_NVIC_EnableIRQ(EXTI15_IRQn);

}

/* USER CODE BEGIN 4 */

/* Routes printf()/_write() (Core/Src/syscalls.c) to USART1, the ST-Link
 * Virtual COM Port (T.VCP_TX/PA9, T.VCP_RX/PA10) - open a serial terminal
 * on that COM port at 115200 8N1 to see it. Without this, __io_putchar
 * stays an unresolved weak symbol and every printf() call in the project
 * (including netx_main_thread_entry's IP address log) faults instead of
 * printing anything. */
int __io_putchar(int ch)
{
  HAL_UART_Transmit(&huart1, (uint8_t *)&ch, 1, HAL_MAX_DELAY);
  return ch;
}

/* USER CODE END 4 */

void HAL_TIM_PeriodElapsedCallback(TIM_HandleTypeDef *htim)
{
  if (htim->Instance == TIM6)
  {
    HAL_IncTick();
  }
}

void Error_Handler(void)
{
  __disable_irq();
  while (1)
  {
  }
}
